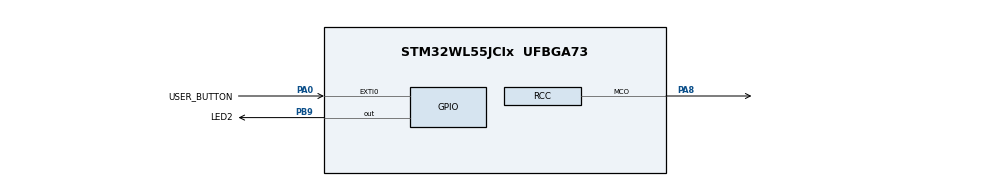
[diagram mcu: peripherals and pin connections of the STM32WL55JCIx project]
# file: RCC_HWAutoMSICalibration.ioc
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Mcu.Family=STM32WL
Mcu.Name=STM32WL55JCIx
Mcu.Package=UFBGA73
NVIC.EXTI0_IRQn=true\:0\:0\:false\:false\:true\:true\:true
NVIC.PriorityGroup=NVIC_PRIORITYGROUP_4
PA0.GPIO_Label=USER_BUTTON
PA0.GPIO_ModeDefaultEXTI=GPIO_MODE_IT_FALLING
PA0.GPIO_PuPd=GPIO_PULLUP
PA0.Signal=GPXTI0
PA8.GPIO_PuPd=GPIO_NOPULL
PA8.GPIO_Speed=GPIO_SPEED_FREQ_VERY_HIGH
PA8.Mode=Clock-out
PA8.Signal=RCC_MCO
PB9.GPIO_Label=LED2
PB9.Signal=GPIO_Output
ProjectManager.HeapSize=0x200
ProjectManager.StackSize=0x400
ProjectManager.TargetToolchain=EWARM V8
RCC.AHBFreq_Value=48000000
RCC.APB1Freq_Value=48000000
RCC.APB1TimFreq_Value=48000000
RCC.APB2Freq_Value=48000000
RCC.APB2TimFreq_Value=48000000
RCC.APB3Freq_Value=48000000
RCC.CortexFreq_Value=48000000
RCC.HCLKFreq_Value=48000000
RCC.HSE_VALUE=8000000
RCC.HSI_VALUE=16000000
RCC.LSE_VALUE=32768
RCC.PLLN=24
RCC.SYSCLKFreq_VALUE=48000000
RCC.SYSCLKSource=RCC_SYSCLKSOURCE_PLLCLK
RCC.VCOOutputFreq_Value=96000000
board=custom

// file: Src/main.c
/* USER CODE BEGIN Header */
/**
  ******************************************************************************
  * @file    Examples_LL/RCC/RCC_HWAutoMSICalibration/Src/main.c
  * @author  MCD Application Team
  * @brief   This example describes how to use the MSI clock source HW auto
  *          calibration to get a precise MSI clock through
  *          the STM32WLxx RCC LL API.
  ******************************************************************************
  * @attention
  *
  * Copyright (c) 2020 STMicroelectronics.
  * All rights reserved.
  *
  * This software is licensed under terms that can be found in the LICENSE file
  * in the root directory of this software component.
  * If no LICENSE file comes with this software, it is provided AS-IS.
  *
  ******************************************************************************
  */
/* USER CODE END Header */
#include "main.h"

/* USER CODE BEGIN PD */

/* Define used to enable time-out management*/
#define USE_TIMEOUT       0

#if (USE_TIMEOUT == 1)
/* LSE time-out value */
#define LSE_STABILIZATION_TIMEOUT           ((uint32_t)125)   /* 125 ms */
#endif /* USE_TIMEOUT */
/* USER CODE END PD */

/* USER CODE BEGIN PV */

__IO uint8_t ubButtonPress = 0;

#if (USE_TIMEOUT == 1)
uint32_t Timeout = 0; /* Variable used for Timeout management */
#endif /* USE_TIMEOUT */

/* USER CODE END PV */

void SystemClock_Config(void);
static void MX_GPIO_Init(void);
/* USER CODE BEGIN PFP */

void     MSICalibration_Process(void);
void     LED_On(void);
#if (USE_TIMEOUT == 1)
void     LED_Blinking(uint32_t Period);
#endif /* USE_TIMEOUT */
void     WaitForUserButtonPress(void);

/* USER CODE END PFP */

int main(void)
{

  /* MCU Configuration--------------------------------------------------------*/

  /* Reset of all peripherals, Initializes the Flash interface and the Systick. */

  /* System interrupt init*/
  NVIC_SetPriorityGrouping(NVIC_PRIORITYGROUP_4);

  /* Configure the system clock */
  SystemClock_Config();

  /* Initialize all configured peripherals */
  MX_GPIO_Init();
  /* USER CODE BEGIN 2 */

  /* Wait Until USER BUTTON is pressed */
  /* LED blinking FAST during waiting time */
  WaitForUserButtonPress();

  /* Start and wait for MSI calibration */
  MSICalibration_Process();

  /* USER CODE END 2 */

  /* Infinite loop */
  while (1)
  {

  }
}

void SystemClock_Config(void)
{
  LL_FLASH_SetLatency(LL_FLASH_LATENCY_2);
  while(LL_FLASH_GetLatency() != LL_FLASH_LATENCY_2)
  {
  }

  LL_PWR_SetRegulVoltageScaling(LL_PWR_REGU_VOLTAGE_SCALE1);
  LL_RCC_MSI_Enable();

   /* Wait till MSI is ready */
  while(LL_RCC_MSI_IsReady() != 1)
  {
  }

  LL_RCC_MSI_EnableRangeSelection();
  LL_RCC_MSI_SetRange(LL_RCC_MSIRANGE_6);
  LL_RCC_MSI_SetCalibTrimming(0);
  LL_RCC_PLL_ConfigDomain_SYS(LL_RCC_PLLSOURCE_MSI, LL_RCC_PLLM_DIV_1, 24, LL_RCC_PLLR_DIV_2);
  LL_RCC_PLL_EnableDomain_SYS();
  LL_RCC_PLL_Enable();

   /* Wait till PLL is ready */
  while(LL_RCC_PLL_IsReady() != 1)
  {
  }

  LL_RCC_SetSysClkSource(LL_RCC_SYS_CLKSOURCE_PLL);

   /* Wait till System clock is ready */
  while(LL_RCC_GetSysClkSource() != LL_RCC_SYS_CLKSOURCE_STATUS_PLL)
  {
  }

  LL_RCC_SetAHBPrescaler(LL_RCC_SYSCLK_DIV_1);
  LL_RCC_SetAHB3Prescaler(LL_RCC_SYSCLK_DIV_1);
  LL_RCC_SetAPB1Prescaler(LL_RCC_APB1_DIV_1);
  LL_RCC_SetAPB2Prescaler(LL_RCC_APB2_DIV_1);

  LL_Init1msTick(48000000);

  /* Update CMSIS variable (which can be updated also through SystemCoreClockUpdate function) */
  LL_SetSystemCoreClock(48000000);
  LL_RCC_ConfigMCO(LL_RCC_MCO1SOURCE_SYSCLK, LL_RCC_MCO1_DIV_1);
}

static void MX_GPIO_Init(void)
{
  LL_EXTI_InitTypeDef EXTI_InitStruct = {0};
  LL_GPIO_InitTypeDef GPIO_InitStruct = {0};

  /* GPIO Ports Clock Enable */
  LL_AHB2_GRP1_EnableClock(LL_AHB2_GRP1_PERIPH_GPIOB);
  LL_AHB2_GRP1_EnableClock(LL_AHB2_GRP1_PERIPH_GPIOA);

  /**/
  LL_GPIO_ResetOutputPin(LED2_GPIO_Port, LED2_Pin);

  /**/
  GPIO_InitStruct.Pin = LED2_Pin;
  GPIO_InitStruct.Mode = LL_GPIO_MODE_OUTPUT;
  GPIO_InitStruct.Speed = LL_GPIO_SPEED_FREQ_LOW;
  GPIO_InitStruct.OutputType = LL_GPIO_OUTPUT_PUSHPULL;
  GPIO_InitStruct.Pull = LL_GPIO_PULL_NO;
  LL_GPIO_Init(LED2_GPIO_Port, &GPIO_InitStruct);

  /**/
  GPIO_InitStruct.Pin = LL_GPIO_PIN_8;
  GPIO_InitStruct.Mode = LL_GPIO_MODE_ALTERNATE;
  GPIO_InitStruct.Speed = LL_GPIO_SPEED_FREQ_VERY_HIGH;
  GPIO_InitStruct.OutputType = LL_GPIO_OUTPUT_PUSHPULL;
  GPIO_InitStruct.Pull = LL_GPIO_PULL_NO;
  GPIO_InitStruct.Alternate = LL_GPIO_AF_0;
  LL_GPIO_Init(GPIOA, &GPIO_InitStruct);

  /**/
  LL_SYSCFG_SetEXTISource(LL_SYSCFG_EXTI_PORTA, LL_SYSCFG_EXTI_LINE0);

  /**/
  EXTI_InitStruct.Line_0_31 = LL_EXTI_LINE_0;
  EXTI_InitStruct.Line_32_63 = LL_EXTI_LINE_NONE;
  EXTI_InitStruct.LineCommand = ENABLE;
  EXTI_InitStruct.Mode = LL_EXTI_MODE_IT;
  EXTI_InitStruct.Trigger = LL_EXTI_TRIGGER_FALLING;
  LL_EXTI_Init(&EXTI_InitStruct);

  /**/
  LL_GPIO_SetPinPull(USER_BUTTON_GPIO_Port, USER_BUTTON_Pin, LL_GPIO_PULL_UP);

  /**/
  LL_GPIO_SetPinMode(USER_BUTTON_GPIO_Port, USER_BUTTON_Pin, LL_GPIO_MODE_INPUT);

  /* EXTI interrupt init*/
  NVIC_SetPriority(EXTI0_IRQn, NVIC_EncodePriority(NVIC_GetPriorityGrouping(),0, 0));
  NVIC_EnableIRQ(EXTI0_IRQn);

}

/* USER CODE BEGIN 4 */
/**
  * @brief  Function to process MSI Calibration
  * @param  None
  * @retval None
  */
void MSICalibration_Process(void)
{
  /* LSE configuration and activation */
  LL_PWR_EnableBkUpAccess();

  /* Enable LSE */
  LL_RCC_ForceBackupDomainReset();
  LL_RCC_ReleaseBackupDomainReset();
  LL_RCC_LSE_SetDriveCapability(LL_RCC_LSEDRIVE_LOW);
  LL_RCC_LSE_Enable();
#if (USE_TIMEOUT == 1)
  Timeout = LSE_STARTUP_TIMEOUT;
#endif /* USE_TIMEOUT */
  while (LL_RCC_LSE_IsReady() != 1)
  {
#if (USE_TIMEOUT == 1)
    /* Check Systick counter flag to decrement the time-out value */
    if (LL_SYSTICK_IsActiveCounterFlag())
    {
      if (Timeout-- == 0)
      {
        /* Time-out occurred. Return an error */
        LED_Blinking(LED_BLINK_ERROR);
      }
    }
#endif /* USE_TIMEOUT */
  };

  /* Enable LSE system clock to use it by MSI PLL mode */
  LL_RCC_LSE_EnablePropagation();

  /* Wait LSE system clock ready flag*/
#if (USE_TIMEOUT == 1)
  Timeout = LSE_STABILIZATION_TIMEOUT; /* Stabilization time required to wait until clock is forwarded to the system (4096 cycles)*/
#endif /* USE_TIMEOUT */
  while (LL_RCC_LSE_IsPropagationReady() != 1)
  {
#if (USE_TIMEOUT == 1)
    /* Check Systick counter flag to decrement the time-out value */
    if (LL_SYSTICK_IsActiveCounterFlag())
    {
      if (Timeout-- == 0)
      {
        /* Time-out occurred. Return an error */
        LED_Blinking(LED_BLINK_ERROR);
      }
    }
#endif /* USE_TIMEOUT */
  };

  /* Enable MSI clock PLL */
  LL_RCC_MSI_EnablePLLMode();

  /* Calibration success*/
  LED_On();
}

/**
  * @brief  Turn-on LED2
  * @param  None
  * @retval None
  */
void LED_On(void)
{
  /* Turn LED2 on */
  LL_GPIO_SetOutputPin(LED2_GPIO_Port, LED2_Pin);
}

#if (USE_TIMEOUT == 1)
/**
  * @brief  Set LED2 to Blinking mode for an infinite loop (toggle period based on value provided as input parameter).
  * @param  Period : Period of time (in ms) between each toggling of LED
  *   This parameter can be user defined values. Pre-defined values used in that example are :
  *     @arg LED_BLINK_FAST : Fast Blinking
  *     @arg LED_BLINK_SLOW : Slow Blinking
  *     @arg LED_BLINK_ERROR : Error specific Blinking
  * @retval None
  */
void LED_Blinking(uint32_t Period)
{
  /* Turn LED2 on */
  LL_GPIO_SetOutputPin(LED2_GPIO_Port, LED2_Pin);

  /* Toggle IO in an infinite loop */
  while (1)
  {
    /* Error if LED2 is slowly blinking (1 sec. period) */
    LL_GPIO_TogglePin(LED2_GPIO_Port, LED2_Pin);
    LL_mDelay(Period);
  }
}
#endif /* USE_TIMEOUT */

/**
  * @brief  Wait for user push button press to start transfer.
  * @param  None
  * @retval None
  */
void WaitForUserButtonPress(void)
{
  while (ubButtonPress == 0)
  {
    /* Fast LED Toggle in waiting user action */
    LL_GPIO_TogglePin(LED2_GPIO_Port, LED2_Pin);
    LL_mDelay(LED_BLINK_FAST);
  }
}

/******************************************************************************/
/*   USER IRQ HANDLER TREATMENT                                               */
/******************************************************************************/
/**
  * @brief  Function to manage Button push
  * @param  None
  * @retval None
  */
void UserButton_Callback(void)
{
  ubButtonPress = 1;
}

/* USER CODE END 4 */

void Error_Handler(void)
{
}
